# SF32LB57x register map
File version: 1.0
CPU: CM33 r0p1, little endian, MPU, FPU, 3 interrupt priority bits
Registers are 32-bit, read-write, reset 0x0 unless marked. A register's access mark holds for its fields unless they carry their own. Offsets are from the block's base; [hi:lo] are bit positions; {n}, {i} and the like mark numbered series; 'fields as' and 'values as' point back to an identical list.

## PWM1
Base 0x500B3000
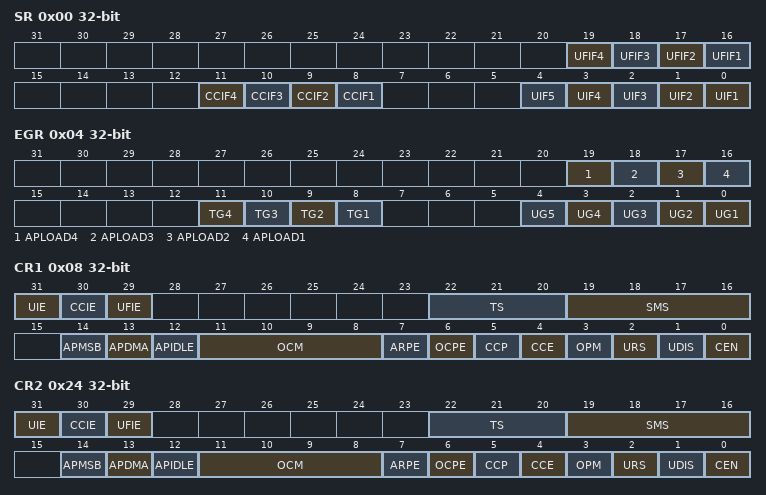
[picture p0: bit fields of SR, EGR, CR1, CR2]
0x00 SR — Interrupt status register
  [19] UFIF4 — Channel 4 FIFO underflow interrupt flag
  [18] UFIF3 — Channel 3 FIFO underflow interrupt flag
  [17] UFIF2 — Channel 2 FIFO underflow interrupt flag
  [16] UFIF1 — Channel 1 FIFO underflow interrupt flag 0: No FIFO underflow. 1: FIFO underflow occur
  [11] CCIF4 — Channel 4 compare interrupt flag
  [10] CCIF3 — Channel 3 compare interrupt flag
  [9] CCIF2 — Channel 2 compare interrupt flag
  [8] CCIF1 — Channel 1 compare interrupt flag This flag is set by hardware when the counter matches the compare value. It is cleared by software. 0: No match. 1: The content of the counter CNTx has matched the content of the CCRx register.
  [n-1] UIF{n} (n=2..5) — Channel {n} update interrupt flag
  [0] UIF1 — Channel 1 update interrupt flag This bit is set by hardware on an update event. It is cleared by software. 0: No update occurred 1: Update interrupt pending. This bit is set by hardware when the registers are updated: - At overflow regarding the repetition counter value (update if repetition counter = 0) and if UDIS=0 in the CRx register. - When CNT is reinitialized by software using the UG bit in EGR register, if URS=0 and UDIS=0 in the CRx register. - When CNT is reinitialized by a trigger event, if URS=0 and UDIS=0 in the CRx register.
0x04 EGR — Event generation register
  [19] APLOAD4 — Channel 4 load data for arbitary pulse
  [18] APLOAD3 — Channel 3 load data for arbitary pulse
  [17] APLOAD2 — Channel 2 load data for arbitary pulse
  [16] APLOAD1 — Channel 1 load data for arbitary pulse This bit can be set by software. It is automatically cleared by hardware if first FIFO byte is ready. write 0: No action write 1: reset fifo, and start data load if DMA enabled. In arbitary pulse mode, data must be pre-loaded before counter starts. By setting APLOAD, data fifo will be reset, then data should be filled by DMA or CPU. read 0: first FIFO byte ready read 1: first FIFO byte not ready yet
  [11] TG4 — Channel 4 trigger generation
  [10] TG3 — Channel 3 trigger generation
  [9] TG2 — Channel 2 trigger generation
  [8] TG1 — Channel 1 trigger generation This bit is set by software in order to generate an event, it is automatically cleared by hardware. 0: No action 1: trigger counter in slave reset/trigger mode.
  [n-1] UG{n} (n=2..5) — Channel {n} update generation
  [0] UG1 — Channel 1 update generation This bit can be set by software, it is automatically cleared by hardware. 0: No action 1: Re-initialize the counter and generates an update of the registers. Note that the prescaler counter is cleared too (anyway the prescaler ratio is not affected). The counter is cleared.
0x08 CR1 — control register for channel 1
  [31] UIE — Channel update interrupt enable 0: Update interrupt disabled. 1: Update interrupt enabled
  [30] CCIE — Channel compare interrupt enable 0: CC interrupt disabled. 1: CC interrupt enabled
  [29] UFIE — Channel FIFO underflow interrupt enable 0: FIFO underflow interrupt disabled. 1: FIFO underflow interrupt enabled
  [22:20] TS — Trigger selection This bit-field selects the trigger input to be used to synchronize the counter. 000: Internal Trigger 0 (ITR0) 001: Internal Trigger 1 (ITR1) 010: Internal Trigger 2 (ITR2) 011: Internal Trigger 3 (ITR3) Note: These bits must be changed only when they are not used (e.g. when SMS=000) to avoid wrong edge detections at the transition.
  [19:16] SMS — Slave mode selection When external signals are selected the active edge of the trigger signal (TRGI) is linked to the polarity selected on the external input. 0000: Slave mode disabled - if CEN = ‘1 then the prescaler is clocked directly by the internal clock. 0100: Reset Mode - Rising edge of the selected trigger input (TRGI) reinitializes the counter and generates an update of the registers. 0101: Gated Mode - The counter clock is enabled when the trigger input (TRGI) is high. The counter stops (but is not reset) as soon as the trigger becomes low. Both start and stop of the counter are controlled. 0110: Trigger Mode - The counter starts at a rising edge of the trigger TRGI (but it is not reset). Only the start of the counter is controlled. 1000: Combined reset + trigger mode - Rising edge of the selected trigger input (TRGI) reinitializes the counter, generates an update of the registers and starts the counter.
  [14] APMSB — Most significant bit first in arbitary pulse mode 0: output from LSB of each byte in FIFO 1: output from MSB of each byte in FIFO
  [13] APDMA — Enable DMA in arbitary pulse mode 0: DMA not enabled, data should be filled by CPU 1: DMA enabled. Data will be filled by DMA after APLOAD set.
  [12] APIDLE — Default output level in arbitary pulse mode when counter not enabled 0: default output is low 1: default output is high
  [11:8] OCM — Output compare mode These bits define the behavior of the output reference signal. 0000: Frozen - The comparison between the output compare register CCRx and the counter CNTx has no effect on the outputs.(this mode is used to generate a timing base). 0001: Set to active level on match. Output signal is forced active when the counter CNTx matches CCRx. 0010: Set to inactive level on match. OC1REF signal is forced inactive when the counter CNTx matches CCRx. 0011: Toggle - output toggles when CNTx=CCRx. 0100: Force to inactive level. 0101: Force to active level. 0110: PWM mode 1 - Output is active as long as CNTxltCCRx else inactive. 0111: PWM mode 2 - Output is inactive as long as CNTxltCCRx else active. 1000: Arbitary pulse mode. Output is generated according to FIFO data filled by DMA or CPU. others: Reserved
  [7] ARPE — Auto-reload preload enable 0: ARRx register is not buffered 1: ARRx register is buffered
  [6] OCPE — Output compare preload enable 0: Preload register on CCRx disabled. CCRx can be written at anytime, the new value is taken in account immediately. 1: Preload register on CCRx enabled. Read/Write operations access the preload register. CCRx preload value is loaded in the active register at each update event.
  [5] CCP — Compare output Polarity. 0: output active high 1: output active low
  [4] CCE — Compare output enable 0: Off - output is not active. No push-pull output. 1: On - output active.
  [3] OPM — One-pulse mode 0: Counter is not stopped at update event 1: Counter stops counting at the next update event (clearing the bit CEN)
  [2] URS — Update request source This bit is set and cleared by software to select the UEV event sources. 0: Any of the following events generate an update interrupt if enabled. These events can be: – Counter overflow – Setting the UG bit – Update generation through the slave mode controller 1: Only counter overflow generates an update interrupt if enabled.
  [1] UDIS — Update disable This bit is set and cleared by software to enable/disable UEV event generation. 0: UEV enabled. The Update (UEV) event is generated by one of the following events: – Counter overflow/underflow – Setting the UG bit – Update generation through the slave mode controller Buffered registers are then loaded with their preload values. 1: UEV disabled. The Update event is not generated, shadow registers keep their value (ARRx, PSCx, CCRx). However the counter and the prescaler are reinitialized if the UG bit is set or if a hardware reset is received from the slave mode controller.
  [0] CEN — Counter enable 0: Counter disabled 1: Counter enabled Note: Gated mode can work only if the CEN bit has been previously set by software. However trigger mode can set the CEN bit automatically by hardware. CEN is cleared automatically in one-pulse mode, when an update event occurs.
0x0C CNT1 — Counter for channel 1
  [31:0] CNT — current counter value
0x10 PSC1 — Prescaler for channel 1
  [15:0] PSC — Prescaler value The counter clock frequency is fpclk/(PSC+1). PSC contains the value to be loaded in the active prescaler register at each update event (including when the counter is cleared through UG bit of EGR register or through trigger controller when configured in “reset mode”).
0x14 ARR1 — Auto-reload register for channel 1
  [31:0] ARR — Auto-reload value ARR is the value to be loaded in the actual auto-reload register. In arbitary mode, ARR defines the total output bit of one PWM period.
0x18 RCR1 — Repetition counter register for channel 1
  [15:0] REP — Repetition counter value These bits allow the user to set-up the update rate of the compare registers (i.e. periodic transfers from preload to active registers) when preload registers are enable, as well as the update interrupt generation rate, if this interrupt is enable. Each time the REP_CNT related downcounter reaches zero, an update event is generated and it restarts counting from REP value. As REP_CNT is reloaded with REP value only at the repetition update event, any write to the RCRx register is not taken in account until the next repetition update event. It means in PWM mode (REP+1) corresponds to the number of PWM periods.
{0x0+0x1C*i} CCR{i} (i=1..4) — Compare register for channel {i}
  [31:0] CCR — Compare value CCR is the value to be loaded in the actual compare register (preload value).It is loaded permanently if the preload feature is not selected in the CR register (bit OCPE). Else the preload value is copied in the active compare register when an update event occurs. The active compare register contains the value to be compared to the counter and signaled on output.
{0x4+0x1C*i} FIFO{i} (i=1..4) — FIFO for channel {i}
  [7:0] DATA — Entry of data FIFO in arbitary pulse mode. DMA or CPU will write data to this register to fill data FIFO.
0x24 CR2 — control register for channel 2
  fields as CR1
0x28 CNT2 — Counter for channel 2
  [31:0] CNT — current counter value
0x2C PSC2 — Prescaler for channel 2
  fields as PSC1
0x30 ARR2 — Auto-reload register for channel 2
  fields as ARR1
0x34 RCR2 — Repetition counter register for channel 2
  fields as RCR1
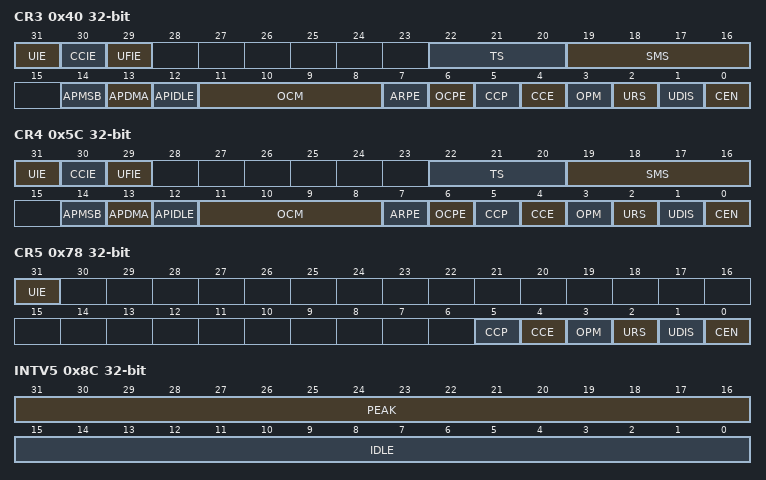
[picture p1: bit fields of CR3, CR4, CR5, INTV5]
0x40 CR3 — control register for channel 3
  fields as CR1
0x44 CNT3 — Counter for channel 3
  [31:0] CNT — current counter value
0x48 PSC3 — Prescaler for channel 3
  fields as PSC1
0x4C ARR3 — Auto-reload register for channel 3
  fields as ARR1
0x50 RCR3 — Repetition counter register for channel 3
  fields as RCR1
0x5C CR4 — control register for channel 4
  fields as CR1
0x60 CNT4 — Counter for channel 4
  [31:0] CNT — current counter value
0x64 PSC4 — Prescaler for channel 4
  fields as PSC1
0x68 ARR4 — Auto-reload register for channel 4
  fields as ARR1
0x6C RCR4 — Repetition counter register for channel 4
  fields as RCR1
0x78 CR5 — control register for channel 5
  [31] UIE — Channel update interrupt enable 0: Update interrupt disabled. 1: Update interrupt enabled
  [5] CCP — Compare output Polarity. 0: output active high 1: output active low
  [4] CCE — Compare output enable 0: Off - output is not active. No push-pull output. 1: On - output active.
  [3] OPM — One-pulse mode 0: Counter is not stopped at update event 1: Counter stops counting at the next update event (clearing the bit CEN)
  [2] URS — Update request source This bit is set and cleared by software to select the UEV event sources. 0: Any of the following events generate an update interrupt if enabled. These events can be: – Counter overflow – Setting the UG bit – Update generation through the slave mode controller 1: Only counter overflow generates an update interrupt if enabled.
  [1] UDIS — Update disable This bit is set and cleared by software to enable/disable UEV event generation. 0: UEV enabled. The Update (UEV) event is generated by one of the following events: – Counter overflow/underflow – Setting the UG bit – Update generation through the slave mode controller Buffered registers are then loaded with their preload values. 1: UEV disabled. The Update event is not generated, shadow registers keep their value (ARRx, PSCx, CCRx). However the counter and the prescaler are reinitialized if the UG bit is set or if a hardware reset is received from the slave mode controller.
  [0] CEN — Counter enable 0: Counter disabled 1: Counter enabled Note: Gated mode can work only if the CEN bit has been previously set by software. However trigger mode can set the CEN bit automatically by hardware. CEN is cleared automatically in one-pulse mode, when an update event occurs.
0x7C CNT5 — Counter for channel 5
  [15:0] CNT — Current counter value. Will be cleared if CEN=0.
0x80 PSC5 — Prescaler for channel 5
  fields as PSC1
0x84 ARR5 reset 0x100 — Auto-reload register for channel 5
  [15:0] ARR — Auto-reload value ARR is the value to be loaded in the actual auto-reload register. ARR can be used to adjust brightness of breath light. Larger ARR leads to lower brightness.
0x88 RCR5 — Repetition counter register for channel 5
  [7:0] REP — Repetition counter value PWM will repeat (REP+1) times in each step of breath waveform.
0x8C INTV5 — Interval of breath wave for channel 5
  [31:16] PEAK — Peak duration of breath light waveform. PWM will repeat (PEAK+1) times for peak duration.
  [15:0] IDLE — Idle interval between two breath light waveform. PWM will repeat (PEAK+1) times for idle interval.
